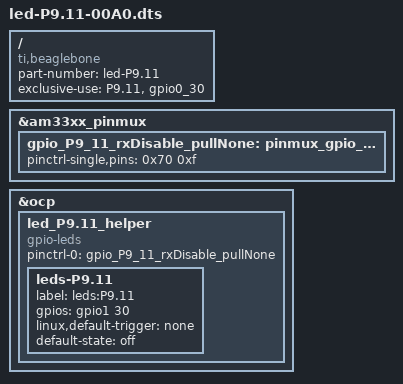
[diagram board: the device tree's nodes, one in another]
/*
* Easy gpio mux control of "P9.11" ("gpio0_30")
*/
/dts-v1/;
/plugin/;

/ {
	compatible = "ti,beaglebone", "ti,beaglebone-black";

	/* identification */
	part-number = "led-P9.11";
	/* version = "00A0"; */

	/* state the resources this cape uses */
	exclusive-use =
		/* the pin header uses */
		"P9.11",

		/* the hardware IP uses */
		"gpio0_30";
	
	
	/* rxDisable_pullNone state */
	fragment@0 {
		target = <&am33xx_pinmux>;
		__overlay__ {
			gpio_P9_11_rxDisable_pullNone: pinmux_gpio_P9.11_rxDisable_pullNone {
				pinctrl-single,pins = <
					0x70 0xf
				>;
			};
		};
	};

	fragment@1 {
		target = <&ocp>;
		__overlay__ {
			led_P9.11_helper {
				compatible = "gpio-leds";
				pinctrl-names = "default";
				pinctrl-0 = <&gpio_P9_11_rxDisable_pullNone>;
				
				leds-P9.11 {
					label = "leds:P9.11";
					gpios = <&gpio1 30 0>;
					linux,default-trigger = "none";
					default-state = "off";
				};
			};
			
		};
	};

};
